# CH583SFR register map
Vendor: WCH Ltd.; Series: CH58x; File version: 1.1
WCH wireless MCU CH58x Family Support, Drivers
CPU: RISC-V r0p0, little endian, no MPU, no FPU, 2 interrupt priority bits
Registers are 8-bit, read-write, reset 0x0 unless marked. A register's access mark holds for its fields unless they carry their own. Offsets are from the block's base; lines under a group give offsets from that group; [hi:lo] are bit positions; {n}, {i} and the like mark numbered series; 'fields as' and 'values as' point back to an identical list; <NAME> marks a mode.

## Memory map
0x40001000 SYS size 0x400 — System Control Register
0x40002000 TMR0 size 0x400 — Timer0 register
0x40002400 TMR1 size 0x400 — Timer1 register
0x40002800 TMR2 size 0x400 — Timer2 register
0x40002C00 TMR3 size 0x400 — Timer3 register
0x40003000 UART0 size 0x400
0x40003400 UART1 size 0x400
0x40003800 UART2 size 0x400
0x40003C00 UART3 size 0x400
0x40004000 SPI0 size 0x400
0x40004400 SPI1 size 0x400
0x40004800 I2C size 0x400
0x40005000 PWMx size 0x400
0x40008000 USB size 0x400
0x40008400 USB2 size 0x400
0x4000C000 BLE size 0x1400
0xE000E000 PFIC size 0x1000 — Program Fast Interrupt Controller
0xE000F000 Systick size 0x100

## Interrupts
16 TMR0 (SYS, TMR0) — TMR0_IRQHandler
17 GPIO_A (SYS) — GPIO_IRQHandler
18 GPIO_B (SYS) — GPIO_IRQHandler
19 SPI0 (SYS, SPI0) — SPI0_IRQHandler
20 BLEB (SYS, BLE) — BB_IRQHandler
21 BLEL (SYS, BLE) — LLE_IRQHandler
22 USB (SYS, USB) — USB_IRQHandler
23 USB2 (SYS, USB2) — USB2_IRQHandler
24 TMR1 (SYS, TMR1) — TMR1_IRQHandler
25 TMR2 (SYS, TMR2) — TMR2_IRQHandler
26 UART0 (SYS, UART0) — UART0_IRQHandler
27 UART1 (SYS, UART1) — UART1_IRQHandler
28 RTC (SYS) — RTC_IRQHandler
29 ADC (SYS) — ADC_IRQHandler
30 I2C (SYS, I2C) — I2C_IRQHandler
31 PWMX_SPI1 (SYS) — PWMX_SPI1_IRQHandler
31 PWMx — PPWMX_SPI1_IRQHandler
31 SPI1 — PPWMX_SPI1_IRQHandler
32 TMR3 (SYS, TMR3) — TMR3_IRQHandler
33 UART2 (SYS, UART2) — UART2_IRQHandler
34 UART3 (SYS, UART3) — UART3_IRQHandler
35 WDOG_BAT (SYS) — WDT_IRQHandler

## TMR2 — Timer2 register
Base 0x40002800
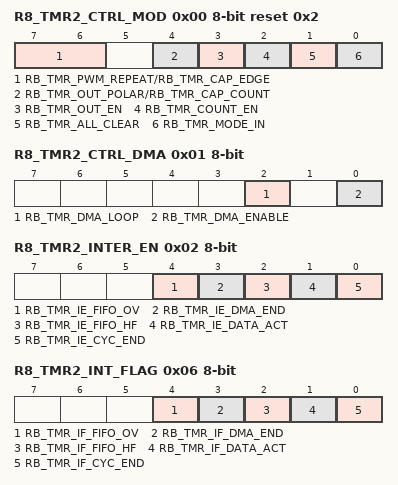
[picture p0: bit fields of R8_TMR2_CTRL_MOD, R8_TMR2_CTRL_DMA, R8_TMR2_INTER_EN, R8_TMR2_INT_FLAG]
0x00 R8_TMR2_CTRL_MOD reset 0x2 — RW, TMR2 mode control
  [7:6] RB_TMR_PWM_REPEAT/RB_TMR_CAP_EDGE — RW, timer PWM repeat mode: 00=1, 01=4, 10=8, 11-16;RW, timer capture edge mode: 00=disable, 01=edge change, 10=fall to fall, 11-rise to rise
  [4] RB_TMR_OUT_POLAR/RB_TMR_CAP_COUNT — RW, timer PWM output polarity: 0=default low and high action, 1=default high and low action;RW, count sub-mode if RB_TMR_MODE_IN=1: 0=capture, 1=count
  [3] RB_TMR_OUT_EN — RW, timer output enable
  [2] RB_TMR_COUNT_EN — RW, timer count enable
  [1] RB_TMR_ALL_CLEAR — RW, force clear timer FIFO and count
  [0] RB_TMR_MODE_IN — RW, timer in mode: 0=timer_PWM, 1=capture_count
0x01 R8_TMR2_CTRL_DMA — RW, TMR2 DMA control
  [2] RB_TMR_DMA_LOOP — RW, timer1_2 DMA address loop enable
  [0] RB_TMR_DMA_ENABLE — RW, timer1_2 DMA enable
0x02 R8_TMR2_INTER_EN — RW, TMR2 interrupt enable
  [4] RB_TMR_IE_FIFO_OV — RW, enable interrupt for timer FIFO overflow
  [3] RB_TMR_IE_DMA_END — RW, enable interrupt for timer1/2 DMA completion
  [2] RB_TMR_IE_FIFO_HF — RW, enable interrupt for timer FIFO half (capture fifo >=4 or PWM fifo less than 3)
  [1] RB_TMR_IE_DATA_ACT — RW, enable interrupt for timer capture input action or PWM trigger
  [0] RB_TMR_IE_CYC_END — RW, enable interrupt for timer capture count timeout or PWM cycle end
0x06 R8_TMR2_INT_FLAG — RW1, TMR2 interrupt flag
  [4] RB_TMR_IF_FIFO_OV — RW1, interrupt flag for timer FIFO overflow
  [3] RB_TMR_IF_DMA_END — RW1, interrupt flag for timer1/2 DMA completion
  [2] RB_TMR_IF_FIFO_HF — RW1, interrupt flag for timer FIFO half (capture fifo >=4 or PWM fifo less than 3
  [1] RB_TMR_IF_DATA_ACT — RW1, interrupt flag for timer capture input action or PWM trigger
  [0] RB_TMR_IF_CYC_END — RW1, interrupt flag for timer capture count timeout or PWM cycle end
0x07 R8_TMR2_FIFO_COUNT ro reset not defined — RO, TMR2 FIFO count status
  [7:0] R8_TMR2_FIFO_COUNT — RW, TMR2 FIFO count status
0x08 R32_TMR2_COUNT 32-bit ro reset not defined — RO, TMR2 current count
  [31:0] R32_TMR2_COUNT — RW, TMR2 current count
0x0C R32_TMR2_CNT_END 32-bit reset not defined — RW, TMR2 end count value, only low 26 bit
  [31:0] R32_TMR2_COUNT — RW, TMR2 current count
0x10 R32_TMR2_COUNT 32-bit — RO, TMR2 FIFO register, only low 26 bit
  [31:0] R32_TMR2_FIFO — RW, TMR2 current count
0x14 R16_TMR2_DMA_NOW 16-bit ro — RO, TMR2 DMA current address
  [31:0] R32_TMR2_FIFO — RW, TMR2 current count
0x18 R16_TMR2_DMA_BEG 16-bit — RW, TMR2 DMA begin address
  [31:0] R16_TMR2_DMA_BEG
0x1C R16_TMR2_DMA_END 16-bit — RW, TMR2 DMA end address
  [31:0] R16_TMR2_DMA_END
